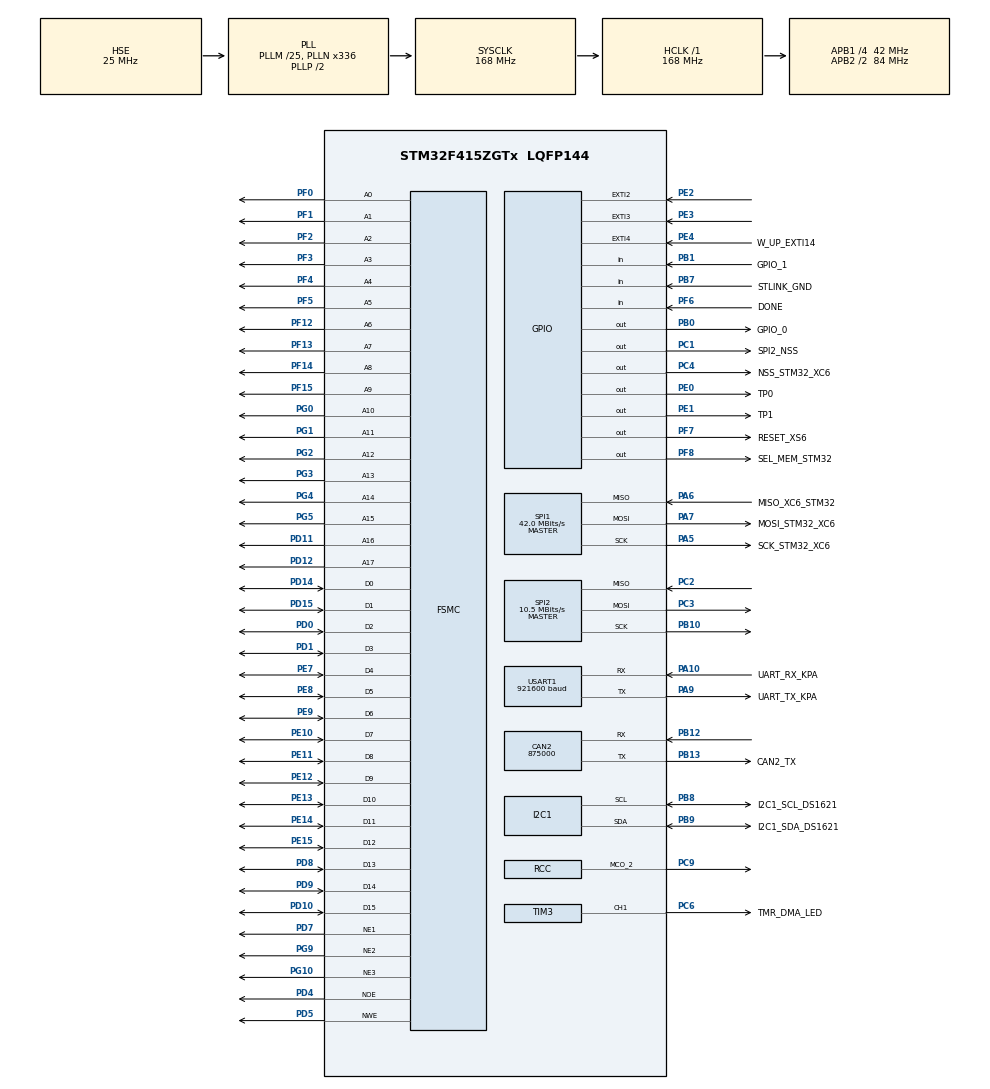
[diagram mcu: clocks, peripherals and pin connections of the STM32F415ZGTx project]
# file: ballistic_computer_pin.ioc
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CAN2.CalculateBaudRate=875000
CAN2.CalculateTimeBit=1142
CAN2.CalculateTimeQuantum=380.95238095238096
Dma.Request0=USART1_RX
Dma.Request1=USART1_TX
Dma.Request2=TIM3_CH1/TRIG
Dma.TIM3_CH1/TRIG.2.Direction=DMA_MEMORY_TO_PERIPH
Dma.TIM3_CH1/TRIG.2.FIFOMode=DMA_FIFOMODE_DISABLE
Dma.TIM3_CH1/TRIG.2.Instance=DMA1_Stream4
Dma.TIM3_CH1/TRIG.2.MemDataAlignment=DMA_MDATAALIGN_WORD
Dma.TIM3_CH1/TRIG.2.MemInc=DMA_MINC_ENABLE
Dma.TIM3_CH1/TRIG.2.Mode=DMA_NORMAL
Dma.TIM3_CH1/TRIG.2.PeriphDataAlignment=DMA_PDATAALIGN_WORD
Dma.TIM3_CH1/TRIG.2.PeriphInc=DMA_PINC_DISABLE
Dma.TIM3_CH1/TRIG.2.Priority=DMA_PRIORITY_HIGH
Dma.USART1_RX.0.Direction=DMA_PERIPH_TO_MEMORY
Dma.USART1_RX.0.FIFOMode=DMA_FIFOMODE_DISABLE
Dma.USART1_RX.0.Instance=DMA2_Stream2
Dma.USART1_RX.0.MemDataAlignment=DMA_MDATAALIGN_BYTE
Dma.USART1_RX.0.MemInc=DMA_MINC_ENABLE
Dma.USART1_RX.0.Mode=DMA_CIRCULAR
Dma.USART1_RX.0.PeriphDataAlignment=DMA_PDATAALIGN_BYTE
Dma.USART1_RX.0.PeriphInc=DMA_PINC_DISABLE
Dma.USART1_RX.0.Priority=DMA_PRIORITY_LOW
Dma.USART1_TX.1.Direction=DMA_MEMORY_TO_PERIPH
Dma.USART1_TX.1.FIFOMode=DMA_FIFOMODE_DISABLE
Dma.USART1_TX.1.Instance=DMA2_Stream7
Dma.USART1_TX.1.MemDataAlignment=DMA_MDATAALIGN_BYTE
Dma.USART1_TX.1.MemInc=DMA_MINC_ENABLE
Dma.USART1_TX.1.Mode=DMA_NORMAL
Dma.USART1_TX.1.PeriphDataAlignment=DMA_PDATAALIGN_BYTE
Dma.USART1_TX.1.PeriphInc=DMA_PINC_DISABLE
Dma.USART1_TX.1.Priority=DMA_PRIORITY_LOW
FREERTOS.Tasks01=defaultTask,24,512,StartDefaultTask,Default,NULL,Dynamic,NULL,NULL;LowLevelTask,9,512,StartLowLevelTask,Default,NULL,Dynamic,NULL,NULL;TerminalTask,15,512,StartTerminalTask,Default,NULL,Dynamic,NULL,NULL
FREERTOS.configTOTAL_HEAP_SIZE=32678
FREERTOS.configUSE_NEWLIB_REENTRANT=1
FSMC.AddressSetupTime1=3
FSMC.AddressSetupTime2=3
FSMC.AddressSetupTime3=5
FSMC.BusTurnAroundDuration1=3
FSMC.BusTurnAroundDuration2=3
FSMC.BusTurnAroundDuration3=5
FSMC.DataSetupTime1=8
FSMC.DataSetupTime2=8
FSMC.DataSetupTime3=15
FSMC.WriteOperation1=FSMC_WRITE_OPERATION_ENABLE
FSMC.WriteOperation2=FSMC_WRITE_OPERATION_ENABLE
FSMC.WriteOperation3=FSMC_WRITE_OPERATION_ENABLE
I2C1.I2C_Mode=I2C_Fast
Mcu.Family=STM32F4
Mcu.Name=STM32F415ZGTx
Mcu.Package=LQFP144
NVIC.DMA1_Stream4_IRQn=true\:5\:0\:false\:false\:true\:true\:false\:true\:true
NVIC.DMA2_Stream2_IRQn=true\:5\:0\:false\:false\:true\:true\:false\:true\:true
NVIC.DMA2_Stream7_IRQn=true\:5\:0\:false\:false\:true\:true\:false\:true\:true
NVIC.EXTI2_IRQn=true\:5\:0\:false\:false\:true\:true\:true\:true\:true
NVIC.PriorityGroup=NVIC_PRIORITYGROUP_4
NVIC.SPI1_IRQn=true\:5\:0\:false\:false\:true\:true\:true\:true\:true
NVIC.TIM1_UP_TIM10_IRQn=true\:15\:0\:false\:false\:true\:false\:false\:true\:true
NVIC.TimeBase=TIM1_UP_TIM10_IRQn
NVIC.TimeBaseIP=TIM10
NVIC.USART1_IRQn=true\:5\:0\:false\:false\:true\:true\:true\:true\:true
PA10.GPIO_Label=UART_RX_KPA
PA10.Mode=Asynchronous
PA10.Signal=USART1_RX
PA13.Mode=Trace_Asynchronous_SW
PA13.Signal=SYS_JTMS-SWDIO
PA14.Mode=Trace_Asynchronous_SW
PA14.Signal=SYS_JTCK-SWCLK
PA5.GPIO_Label=SCK_STM32_XC6
PA5.Mode=Full_Duplex_Master
PA5.Signal=SPI1_SCK
PA6.GPIO_Label=MISO_XC6_STM32
PA6.Mode=Full_Duplex_Master
PA6.Signal=SPI1_MISO
PA7.GPIO_Label=MOSI_STM32_XC6
PA7.Mode=Full_Duplex_Master
PA7.Signal=SPI1_MOSI
PA9.GPIO_Label=UART_TX_KPA
PA9.Mode=Asynchronous
PA9.Signal=USART1_TX
PB0.GPIO_Label=GPIO_0
PB0.Signal=GPIO_Output
PB1.GPIO_Label=GPIO_1
PB1.Signal=GPIO_Input
PB10.Mode=Full_Duplex_Master
PB10.Signal=SPI2_SCK
PB12.Mode=CAN_Activate
PB12.Signal=CAN2_RX
PB13.GPIO_Label=CAN2_TX
PB13.Mode=CAN_Activate
PB13.Signal=CAN2_TX
PB3.Mode=Trace_Asynchronous_SW
PB3.Signal=SYS_JTDO-SWO
PB7.GPIO_Label=STLINK_GND
PB7.GPIO_PuPd=GPIO_PULLUP
PB7.Signal=GPIO_Input
PB8.GPIO_Label=I2C1_SCL_DS1621
PB8.GPIO_Pu=GPIO_PULLUP
PB8.GPIO_Speed=GPIO_SPEED_FREQ_HIGH
PB8.Mode=I2C
PB8.Signal=I2C1_SCL
PB9.GPIO_Label=I2C1_SDA_DS1621
PB9.GPIO_Pu=GPIO_PULLUP
PB9.GPIO_Speed=GPIO_SPEED_FREQ_HIGH
PB9.Mode=I2C
PB9.Signal=I2C1_SDA
PC1.GPIO_Label=SPI2_NSS
PC1.GPIO_Speed=GPIO_SPEED_FREQ_HIGH
PC1.PinState=GPIO_PIN_SET
PC1.Signal=GPIO_Output
PC2.Mode=Full_Duplex_Master
PC2.Signal=SPI2_MISO
PC3.Mode=Full_Duplex_Master
PC3.Signal=SPI2_MOSI
PC4.GPIO_Label=NSS_STM32_XC6
PC4.GPIO_Speed=GPIO_SPEED_FREQ_HIGH
PC4.PinState=GPIO_PIN_SET
PC4.Signal=GPIO_Output
PC6.GPIO_Label=TMR_DMA_LED
PC6.GPIO_Speed=GPIO_SPEED_FREQ_HIGH
PC6.Signal=S_TIM3_CH1
PC9.Mode=Clock-out-2
PC9.Signal=RCC_MCO_2
PD0.Signal=FSMC_D2_DA2
PD1.Signal=FSMC_D3_DA3
PD10.Signal=FSMC_D15_DA15
PD11.Signal=FSMC_A16_CLE
PD12.Signal=FSMC_A17_ALE
PD14.Signal=FSMC_D0_DA0
PD15.Signal=FSMC_D1_DA1
PD4.Signal=FSMC_NOE
PD5.Signal=FSMC_NWE
PD7.Mode=NorPsramChipSelect1_1
PD7.Signal=FSMC_NE1
PD8.Signal=FSMC_D13_DA13
PD9.Signal=FSMC_D14_DA14
PE0.GPIO_Label=TP0
PE0.Signal=GPIO_Output
PE1.GPIO_Label=TP1
PE1.Signal=GPIO_Output
PE10.Signal=FSMC_D7_DA7
PE11.Signal=FSMC_D8_DA8
PE12.Signal=FSMC_D9_DA9
PE13.Signal=FSMC_D10_DA10
PE14.Signal=FSMC_D11_DA11
PE15.Signal=FSMC_D12_DA12
PE2.GPIO_ModeDefaultEXTI=GPIO_MODE_IT_FALLING
PE2.GPIO_PuPd=GPIO_PULLUP
PE2.Signal=GPXTI2
PE3.Signal=GPXTI3
PE4.GPIO_Label=W_UP_EXTI14
PE4.Signal=GPXTI4
PE7.Signal=FSMC_D4_DA4
PE8.Signal=FSMC_D5_DA5
PE9.Signal=FSMC_D6_DA6
PF0.Signal=FSMC_A0
PF1.Signal=FSMC_A1
PF12.Signal=FSMC_A6
PF13.Signal=FSMC_A7
PF14.Signal=FSMC_A8
PF15.Signal=FSMC_A9
PF2.Signal=FSMC_A2
PF3.Signal=FSMC_A3
PF4.Signal=FSMC_A4
PF5.Signal=FSMC_A5
PF6.GPIO_Label=DONE
PF6.Signal=GPIO_Input
PF7.GPIO_Label=RESET_XS6
PF7.Signal=GPIO_Output
PF8.GPIO_Label=SEL_MEM_STM32
PF8.PinState=GPIO_PIN_SET
PF8.Signal=GPIO_Output
PG0.Signal=FSMC_A10
PG1.Signal=FSMC_A11
PG10.Mode=NorPsramChipSelect3_3
PG10.Signal=FSMC_NE3
PG2.Signal=FSMC_A12
PG3.Signal=FSMC_A13
PG4.Signal=FSMC_A14
PG5.Signal=FSMC_A15
PG9.Mode=NorPsramChipSelect2_2
PG9.Signal=FSMC_NE2
PH0-OSC_IN.Mode=HSE-External-Clock-Source
PH0-OSC_IN.Signal=RCC_OSC_IN
PH1-OSC_OUT.Mode=HSE-External-Clock-Source
PH1-OSC_OUT.Signal=RCC_OSC_OUT
ProjectManager.HeapSize=0x4000
ProjectManager.StackSize=0x2000
ProjectManager.TargetToolchain=STM32CubeIDE
RCC.48MHZClocksFreq_Value=84000000
RCC.AHBFreq_Value=168000000
RCC.APB1CLKDivider=RCC_HCLK_DIV4
RCC.APB1Freq_Value=42000000
RCC.APB1TimFreq_Value=84000000
RCC.APB2CLKDivider=RCC_HCLK_DIV2
RCC.APB2Freq_Value=84000000
RCC.APB2TimFreq_Value=168000000
RCC.CortexFreq_Value=168000000
RCC.HCLKFreq_Value=168000000
RCC.HSE_VALUE=25000000
RCC.HSI_VALUE=16000000
RCC.LSE_VALUE=32768
RCC.PLLM=25
RCC.PLLN=336
RCC.PLLSourceVirtual=RCC_PLLSOURCE_HSE
RCC.RCC_MCO2Source=RCC_MCO2SOURCE_HSE
RCC.SYSCLKFreq_VALUE=168000000
RCC.SYSCLKSource=RCC_SYSCLKSOURCE_PLLCLK
RCC.VCOOutputFreq_Value=336000000
SH.FSMC_A0.0=FSMC_A0,18b-a1
SH.FSMC_A0.1=FSMC_A0,10b-a2
SH.FSMC_A0.2=FSMC_A0,10b-a3
SH.FSMC_A1.0=FSMC_A1,18b-a1
SH.FSMC_A1.1=FSMC_A1,10b-a2
SH.FSMC_A1.2=FSMC_A1,10b-a3
SH.FSMC_A10.0=FSMC_A10,18b-a1
SH.FSMC_A11.0=FSMC_A11,18b-a1
SH.FSMC_A12.0=FSMC_A12,18b-a1
SH.FSMC_A13.0=FSMC_A13,18b-a1
SH.FSMC_A14.0=FSMC_A14,18b-a1
SH.FSMC_A15.0=FSMC_A15,18b-a1
SH.FSMC_A16_CLE.0=FSMC_A16,18b-a1
SH.FSMC_A17_ALE.0=FSMC_A17,18b-a1
SH.FSMC_A2.0=FSMC_A2,18b-a1
SH.FSMC_A2.1=FSMC_A2,10b-a2
SH.FSMC_A2.2=FSMC_A2,10b-a3
SH.FSMC_A3.0=FSMC_A3,18b-a1
SH.FSMC_A3.1=FSMC_A3,10b-a2
SH.FSMC_A3.2=FSMC_A3,10b-a3
SH.FSMC_A4.0=FSMC_A4,18b-a1
SH.FSMC_A4.1=FSMC_A4,10b-a2
SH.FSMC_A4.2=FSMC_A4,10b-a3
SH.FSMC_A5.0=FSMC_A5,18b-a1
SH.FSMC_A5.1=FSMC_A5,10b-a2
SH.FSMC_A5.2=FSMC_A5,10b-a3
SH.FSMC_A6.0=FSMC_A6,18b-a1
SH.FSMC_A6.1=FSMC_A6,10b-a2
SH.FSMC_A6.2=FSMC_A6,10b-a3
SH.FSMC_A7.0=FSMC_A7,18b-a1
SH.FSMC_A7.1=FSMC_A7,10b-a2
SH.FSMC_A7.2=FSMC_A7,10b-a3
SH.FSMC_A8.0=FSMC_A8,18b-a1
SH.FSMC_A8.1=FSMC_A8,10b-a2
SH.FSMC_A8.2=FSMC_A8,10b-a3
SH.FSMC_A9.0=FSMC_A9,18b-a1
SH.FSMC_A9.1=FSMC_A9,10b-a2
SH.FSMC_A9.2=FSMC_A9,10b-a3
SH.FSMC_D0_DA0.0=FSMC_D0,16b-d1
SH.FSMC_D0_DA0.1=FSMC_D0,16b-d2
SH.FSMC_D0_DA0.2=FSMC_D0,16b-d3
SH.FSMC_D10_DA10.0=FSMC_D10,16b-d1
SH.FSMC_D10_DA10.1=FSMC_D10,16b-d2
SH.FSMC_D10_DA10.2=FSMC_D10,16b-d3
SH.FSMC_D11_DA11.0=FSMC_D11,16b-d1
SH.FSMC_D11_DA11.1=FSMC_D11,16b-d2
SH.FSMC_D11_DA11.2=FSMC_D11,16b-d3
SH.FSMC_D12_DA12.0=FSMC_D12,16b-d1
SH.FSMC_D12_DA12.1=FSMC_D12,16b-d2
SH.FSMC_D12_DA12.2=FSMC_D12,16b-d3
SH.FSMC_D13_DA13.0=FSMC_D13,16b-d1
SH.FSMC_D13_DA13.1=FSMC_D13,16b-d2
SH.FSMC_D13_DA13.2=FSMC_D13,16b-d3
SH.FSMC_D14_DA14.0=FSMC_D14,16b-d1
SH.FSMC_D14_DA14.1=FSMC_D14,16b-d2
SH.FSMC_D14_DA14.2=FSMC_D14,16b-d3
SH.FSMC_D15_DA15.0=FSMC_D15,16b-d1
SH.FSMC_D15_DA15.1=FSMC_D15,16b-d2
SH.FSMC_D15_DA15.2=FSMC_D15,16b-d3
SH.FSMC_D1_DA1.0=FSMC_D1,16b-d1
SH.FSMC_D1_DA1.1=FSMC_D1,16b-d2
SH.FSMC_D1_DA1.2=FSMC_D1,16b-d3
SH.FSMC_D2_DA2.0=FSMC_D2,16b-d1
SH.FSMC_D2_DA2.1=FSMC_D2,16b-d2
SH.FSMC_D2_DA2.2=FSMC_D2,16b-d3
SH.FSMC_D3_DA3.0=FSMC_D3,16b-d1
SH.FSMC_D3_DA3.1=FSMC_D3,16b-d2
SH.FSMC_D3_DA3.2=FSMC_D3,16b-d3
SH.FSMC_D4_DA4.0=FSMC_D4,16b-d1
SH.FSMC_D4_DA4.1=FSMC_D4,16b-d2
SH.FSMC_D4_DA4.2=FSMC_D4,16b-d3
SH.FSMC_D5_DA5.0=FSMC_D5,16b-d1
SH.FSMC_D5_DA5.1=FSMC_D5,16b-d2
SH.FSMC_D5_DA5.2=FSMC_D5,16b-d3
SH.FSMC_D6_DA6.0=FSMC_D6,16b-d1
SH.FSMC_D6_DA6.1=FSMC_D6,16b-d2
SH.FSMC_D6_DA6.2=FSMC_D6,16b-d3
SH.FSMC_D7_DA7.0=FSMC_D7,16b-d1
SH.FSMC_D7_DA7.1=FSMC_D7,16b-d2
SH.FSMC_D7_DA7.2=FSMC_D7,16b-d3
SH.FSMC_D8_DA8.0=FSMC_D8,16b-d1
SH.FSMC_D8_DA8.1=FSMC_D8,16b-d2
SH.FSMC_D8_DA8.2=FSMC_D8,16b-d3
SH.FSMC_D9_DA9.0=FSMC_D9,16b-d1
SH.FSMC_D9_DA9.1=FSMC_D9,16b-d2
SH.FSMC_D9_DA9.2=FSMC_D9,16b-d3
SH.FSMC_NOE.0=FSMC_NOE,Sram1
SH.FSMC_NOE.1=FSMC_NOE,Sram2
SH.FSMC_NOE.2=FSMC_NOE,Sram3
SH.FSMC_NWE.0=FSMC_NWE,Sram1
SH.FSMC_NWE.1=FSMC_NWE,Sram2
SH.FSMC_NWE.2=FSMC_NWE,Sram3
SH.S_TIM3_CH1.0=TIM3_CH1,PWM Generation1 CH1
SPI1.CalculateBaudRate=42.0 MBits/s
SPI1.Direction=SPI_DIRECTION_2LINES
SPI1.Mode=SPI_MODE_MASTER
SPI1.VirtualType=VM_MASTER
SPI2.BaudRatePrescaler=SPI_BAUDRATEPRESCALER_4
SPI2.CalculateBaudRate=10.5 MBits/s
SPI2.Direction=SPI_DIRECTION_2LINES
SPI2.Mode=SPI_MODE_MASTER
SPI2.VirtualType=VM_MASTER
TIM3.AutoReloadPreload=TIM_AUTORELOAD_PRELOAD_ENABLE
TIM3.Channel-PWM\ Generation1\ CH1=TIM_CHANNEL_1
TIM3.Period=104
USART1.BaudRate=921600
USART1.Parity=PARITY_EVEN
USART1.VirtualMode=VM_ASYNC
USART1.WordLength=WORDLENGTH_9B
VP_CRC_VS_CRC.Mode=CRC_Activate
VP_FREERTOS_VS_CMSIS_V2.Mode=CMSIS_V2
VP_SYS_VS_tim10.Mode=TIM10
VP_TIM3_VS_ClockSourceINT.Mode=Internal
board=custom

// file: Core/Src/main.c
/* USER CODE BEGIN Header */
/**
  ******************************************************************************
  * @file           : main.c
  * @brief          : Main program body
  ******************************************************************************
  * @attention
  *
  * Copyright (c) 2026 STMicroelectronics.
  * All rights reserved.
  *
  * This software is licensed under terms that can be found in the LICENSE file
  * in the root directory of this software component.
  * If no LICENSE file comes with this software, it is provided AS-IS.
  *
  ******************************************************************************
  */
/* USER CODE END Header */
#include "main.h"
#include "cmsis_os.h"
#include "can.h"
#include "crc.h"
#include "dma.h"
#include "i2c.h"
#include "spi.h"
#include "tim.h"
#include "usart.h"
#include "gpio.h"
#include "fsmc.h"

/* USER CODE BEGIN Includes */
#include "ds1621.h"
/* USER CODE END Includes */

void SystemClock_Config(void);
void MX_FREERTOS_Init(void);

/* USER CODE BEGIN 0 */
uint8_t ucHeap[ configTOTAL_HEAP_SIZE ] __attribute__((section(".ccmram"), aligned(8)));
/* USER CODE END 0 */

int main(void)
{

  /* MCU Configuration--------------------------------------------------------*/

  /* Reset of all peripherals, Initializes the Flash interface and the Systick. */
  HAL_Init();

  /* Configure the system clock */
  SystemClock_Config();

  /* Initialize all configured peripherals */
  MX_GPIO_Init();
  MX_DMA_Init();
  MX_SPI1_Init();
  MX_USART1_UART_Init();
  MX_I2C1_Init();
  MX_CAN2_Init();
  MX_SPI2_Init();
  MX_FSMC_Init();
  MX_TIM3_Init();
  MX_CRC_Init();

  /* Init scheduler */
  osKernelInitialize();  /* Call init function for freertos objects (in cmsis_os2.c) */
  MX_FREERTOS_Init();

  /* Start scheduler */
  osKernelStart();

  /* We should never get here as control is now taken by the scheduler */

  /* Infinite loop */
  while (1)
  {

  }
}

void SystemClock_Config(void)
{
  RCC_OscInitTypeDef RCC_OscInitStruct = {0};
  RCC_ClkInitTypeDef RCC_ClkInitStruct = {0};

  /** Configure the main internal regulator output voltage
  */
  __HAL_RCC_PWR_CLK_ENABLE();
  __HAL_PWR_VOLTAGESCALING_CONFIG(PWR_REGULATOR_VOLTAGE_SCALE1);

  /** Initializes the RCC Oscillators according to the specified parameters
  * in the RCC_OscInitTypeDef structure.
  */
  RCC_OscInitStruct.OscillatorType = RCC_OSCILLATORTYPE_HSE;
  RCC_OscInitStruct.HSEState = RCC_HSE_BYPASS;
  RCC_OscInitStruct.PLL.PLLState = RCC_PLL_ON;
  RCC_OscInitStruct.PLL.PLLSource = RCC_PLLSOURCE_HSE;
  RCC_OscInitStruct.PLL.PLLM = 25;
  RCC_OscInitStruct.PLL.PLLN = 336;
  RCC_OscInitStruct.PLL.PLLP = RCC_PLLP_DIV2;
  RCC_OscInitStruct.PLL.PLLQ = 4;
  if (HAL_RCC_OscConfig(&RCC_OscInitStruct) != HAL_OK)
  {
    Error_Handler();
  }

  /** Initializes the CPU, AHB and APB buses clocks
  */
  RCC_ClkInitStruct.ClockType = RCC_CLOCKTYPE_HCLK|RCC_CLOCKTYPE_SYSCLK
                              |RCC_CLOCKTYPE_PCLK1|RCC_CLOCKTYPE_PCLK2;
  RCC_ClkInitStruct.SYSCLKSource = RCC_SYSCLKSOURCE_PLLCLK;
  RCC_ClkInitStruct.AHBCLKDivider = RCC_SYSCLK_DIV1;
  RCC_ClkInitStruct.APB1CLKDivider = RCC_HCLK_DIV4;
  RCC_ClkInitStruct.APB2CLKDivider = RCC_HCLK_DIV2;

  if (HAL_RCC_ClockConfig(&RCC_ClkInitStruct, FLASH_LATENCY_5) != HAL_OK)
  {
    Error_Handler();
  }
  HAL_RCC_MCOConfig(RCC_MCO2, RCC_MCO2SOURCE_HSE, RCC_MCODIV_1);
}

void HAL_TIM_PeriodElapsedCallback(TIM_HandleTypeDef *htim)
{
  if (htim->Instance == TIM10)
  {
    HAL_IncTick();
  }
}

void Error_Handler(void)
{
  __disable_irq();
  while (1)
  {
  }
}

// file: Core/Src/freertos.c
/* USER CODE BEGIN Header */
/**
  ******************************************************************************
  * File Name          : freertos.c
  * Description        : Code for freertos applications
  ******************************************************************************
  * @attention
  *
  * Copyright (c) 2026 STMicroelectronics.
  * All rights reserved.
  *
  * This software is licensed under terms that can be found in the LICENSE file
  * in the root directory of this software component.
  * If no LICENSE file comes with this software, it is provided AS-IS.
  *
  ******************************************************************************
  */
/* USER CODE END Header */

#include "FreeRTOS.h"
#include "task.h"
#include "main.h"
#include "cmsis_os.h"

/* USER CODE BEGIN Includes */
#include "board_support_package.h"
#include "pin_mgmt.h"
#include "rgb_led.h"
#include "ds1621.h"
#include "am1805.h"
#include "terminal.h"
#include "fpga.h"
#include "spi_fpga_bridge.h"
#include "fpga_reg_map.h"
#include "fpga_pwm.h"
#include "fram_recorder.h"
#include "fm22l16.h"

/* USER CODE END Includes */

/* USER CODE BEGIN Variables */
extern LED_Handler_t led_main;

/* USER CODE END Variables */
/* Definitions for defaultTask */
osThreadId_t defaultTaskHandle;
const osThreadAttr_t defaultTask_attributes = {
  .name = "defaultTask",
  .stack_size = 512 * 4,
  .priority = (osPriority_t) osPriorityNormal,
};
/* Definitions for LowLevelTask */
osThreadId_t LowLevelTaskHandle;
const osThreadAttr_t LowLevelTask_attributes = {
  .name = "LowLevelTask",
  .stack_size = 512 * 4,
  .priority = (osPriority_t) osPriorityLow1,
};
/* Definitions for TerminalTask */
osThreadId_t TerminalTaskHandle;
const osThreadAttr_t TerminalTask_attributes = {
  .name = "TerminalTask",
  .stack_size = 512 * 4,
  .priority = (osPriority_t) osPriorityLow7,
};

void StartDefaultTask(void *argument);
void StartLowLevelTask(void *argument);
void StartTerminalTask(void *argument);

void MX_FREERTOS_Init(void); /* (MISRA C 2004 rule 8.1) */

void MX_FREERTOS_Init(void) {

  /* Create the thread(s) */
  /* creation of defaultTask */
  defaultTaskHandle = osThreadNew(StartDefaultTask, NULL, &defaultTask_attributes);

  /* creation of LowLevelTask */
  LowLevelTaskHandle = osThreadNew(StartLowLevelTask, NULL, &LowLevelTask_attributes);

  /* creation of TerminalTask */
  TerminalTaskHandle = osThreadNew(StartTerminalTask, NULL, &TerminalTask_attributes);

}

void StartDefaultTask(void *argument)
{
  /* USER CODE BEGIN StartDefaultTask */

	osThreadSuspend(LowLevelTaskHandle);
	osThreadSuspend(TerminalTaskHandle);

    init_hardware();

	if (test_status_hardware(_B_FAULT_TERMINAL_)) {
		osThreadResume(TerminalTaskHandle);
	}

    osThreadResume(LowLevelTaskHandle);

    for (;;) {

		PIN_Toggle_S(&pin_tp0);
        osDelay(100);
    }
  /* USER CODE END StartDefaultTask */
}

/* USER CODE BEGIN Header_StartLowLevelTask */
float current_temp;
AM1805_Time_t current_time;
char time_str[32];          // Буфер для строки "HH:MM:SS [XT]"

uint16_t test_fpga=0;

/* USER CODE END Header_StartLowLevelTask */
void StartLowLevelTask(void *argument)
{
  /* USER CODE BEGIN StartLowLevelTask */

	for (;;) {
		// 4. Update current temperature
		current_temp = DS1621_GetLastTemperature();

		if (AM1805_GetTime(&current_time) == AM1805_OK) {
			AM1805_FormatFullDateTime(time_str, sizeof(time_str),	&current_time);
		}

		fpga_tgl_bit(66, 2);
		osDelay(500);
	}
  /* USER CODE END StartLowLevelTask */
}

/* USER CODE BEGIN Header_StartTerminalTask */
/**
* @brief Function implementing the TerminalTask thread.
* @param argument: Not used
* @retval None
*/

uint16_t pwm;

/* USER CODE END Header_StartTerminalTask */
void StartTerminalTask(void *argument)
{
  /* USER CODE BEGIN StartTerminalTask */
	/* Infinite loop */
	for (;;) {
		terminal_task();
		PIN_Toggle_S(&pin_tp1);

		fpga_set_bit(ADDR_DEBUG_MISC, B0);
		delay_us(20);
		fpga_clr_bit(ADDR_DEBUG_MISC, B0);

		/*fpga_read(ADDR_DEBUG_FEEDBACK, &test_fpga);
		test_fpga++;
		fpga_write(ADDR_DEBUG_FEEDBACK, test_fpga);*/
		SPI_FPGA_Read(ADDR_S_DEBUG_FEEDBACK, &test_fpga);
		test_fpga+=1;
		SPI_FPGA_Write(ADDR_S_DEBUG_FEEDBACK, test_fpga);

		static bool f;
		if (f){

			fpga_pwm_set_duty(pwm);
			pwm+=4;
			if (pwm==10000)pwm=0;
		}
		f=!f;
	}
  /* USER CODE END StartTerminalTask */
}
